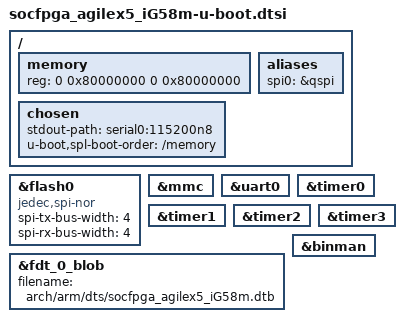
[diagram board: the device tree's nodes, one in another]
// SPDX-License-Identifier:     GPL-2.0
/*
 * U-Boot additions
 *
 * Copyright (C) 2025 iWave Global 
 * IP Support <support.ip@iwave-global.com>
 */

#include "socfpga_agilex5-u-boot.dtsi"
/{
	memory {
		/* 2GB */
		reg = <0 0x80000000 0 0x80000000>;
	};
	

	aliases {
		spi0 = &qspi;
	};

	chosen {
		stdout-path = "serial0:115200n8";
		u-boot,spl-boot-order = &flash0,&mmc,"/memory";
	};
};

&flash0 {
	compatible = "jedec,spi-nor";
	spi-tx-bus-width = <4>;
	spi-rx-bus-width = <4>;
	bootph-all;
	/delete-property/ cdns,read-delay;
};


&mmc {
	bootph-all;
};

&uart0 {
	bootph-all;
};

&timer0 {
	bootph-all;
};

&timer1 {
	bootph-all;
};

&timer2 {
	bootph-all;
};

&timer3 {
	bootph-all;
};

#if !defined(CONFIG_SOCFPGA_SECURE_VAB_AUTH)
&fdt_0_blob {
	filename = "arch/arm/dts/socfpga_agilex5_iG58m.dtb";
};


&binman {
	/delete-node/ kernel;
};
#endif

// Delete the hog
/*/delete-node/ &{/soc/gpio@10c03300/gpio-controller@0/sdio_sel};*/
